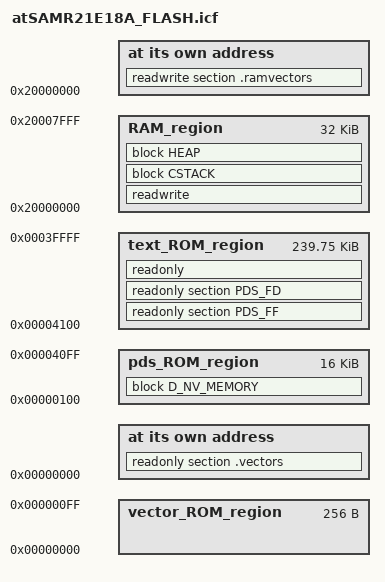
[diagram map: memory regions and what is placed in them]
/**
 * \file
 *
 * \brief Linker script for running in internal FLASH on the SAMR21E18A and SAMR21G18A
 *
 * Copyright (c) 2013 Atmel Corporation. All rights reserved.
 *
 * \asf_license_start
 *
 * \page License
 *
 * Redistribution and use in source and binary forms, with or without
 * modification, are permitted provided that the following conditions are met:
 *
 * 1. Redistributions of source code must retain the above copyright notice,
 *    this list of conditions and the following disclaimer.
 *
 * 2. Redistributions in binary form must reproduce the above copyright notice,
 *    this list of conditions and the following disclaimer in the documentation
 *    and/or other materials provided with the distribution.
 *
 * 3. The name of Atmel may not be used to endorse or promote products derived
 *    from this software without specific prior written permission.
 *
 * 4. This software may only be redistributed and used in connection with an
 *    Atmel microcontroller product.
 *
 * THIS SOFTWARE IS PROVIDED BY ATMEL "AS IS" AND ANY EXPRESS OR IMPLIED
 * WARRANTIES, INCLUDING, BUT NOT LIMITED TO, THE IMPLIED WARRANTIES OF
 * MERCHANTABILITY, FITNESS FOR A PARTICULAR PURPOSE AND NON-INFRINGEMENT ARE
 * EXPRESSLY AND SPECIFICALLY DISCLAIMED. IN NO EVENT SHALL ATMEL BE LIABLE FOR
 * ANY DIRECT, INDIRECT, INCIDENTAL, SPECIAL, EXEMPLARY, OR CONSEQUENTIAL
 * DAMAGES (INCLUDING, BUT NOT LIMITED TO, PROCUREMENT OF SUBSTITUTE GOODS
 * OR SERVICES; LOSS OF USE, DATA, OR PROFITS; OR BUSINESS INTERRUPTION)
 * HOWEVER CAUSED AND ON ANY THEORY OF LIABILITY, WHETHER IN CONTRACT,
 * STRICT LIABILITY, OR TORT (INCLUDING NEGLIGENCE OR OTHERWISE) ARISING IN
 * ANY WAY OUT OF THE USE OF THIS SOFTWARE, EVEN IF ADVISED OF THE
 * POSSIBILITY OF SUCH DAMAGE.
 *
 * \asf_license_stop
 *
 */

/*###ICF### Section handled by ICF editor, don't touch! ****/
/*-Editor annotation file-*/
/* IcfEditorFile="$TOOLKIT_DIR$\config\ide\IcfEditor\a_v1_0.xml" */
/*-Vector table start*/
define symbol __ICFEDIT_vector_start__ = 0x000400000; /*Add for CMSIS*/
/*-Memory Regions-*/
define symbol __ICFEDIT_region_RAM_start__  = 0x20000000;
define symbol __ICFEDIT_region_RAM_end__    = 0x20007FFF;
define symbol __ICFEDIT_region_vector_ROM_start__  = 0x00000000;
define symbol __ICFEDIT_region_vector_ROM_end__    = 0x000000FF;
define symbol __ICFEDIT_region_pds_ROM_start__  = 0x00000100;
define symbol __ICFEDIT_region_pds_ROM_end__    = 0x00040FF;
define symbol __ICFEDIT_region_text_ROM_start__  = 0x004100;
define symbol __ICFEDIT_region_text_ROM_end__    = 0x0003FFFF;

/*-Sizes-*/
define symbol __ICFEDIT_size_cstack__        = 0x800;
define symbol __ICFEDIT_size_heap__          = 0x200;
define symbol D_NV_MEMORY_START = 0x400;
define symbol _D_NV_MEMORY_SIZE = 0x4000;

export symbol __ICFEDIT_vector_start__; /*Add for CMSIS*/
/**** End of ICF editor section. ###ICF###*/

define memory mem with size   = 4G;
define region RAM_region     = mem:[from __ICFEDIT_region_RAM_start__ to __ICFEDIT_region_RAM_end__];
define region vector_ROM_region     = mem:[from __ICFEDIT_region_vector_ROM_start__ to __ICFEDIT_region_vector_ROM_end__];
define region pds_ROM_region        = mem:[from __ICFEDIT_region_pds_ROM_start__ to __ICFEDIT_region_pds_ROM_end__];
define region text_ROM_region       = mem:[from __ICFEDIT_region_text_ROM_start__ to __ICFEDIT_region_text_ROM_end__];

define block CSTACK    with alignment = 8, size = __ICFEDIT_size_cstack__   { };
define block HEAP      with alignment = 8, size = __ICFEDIT_size_heap__     { };
define block D_NV_MEMORY with size = _D_NV_MEMORY_SIZE, alignment = 8 { };

initialize by copy { readwrite };
do not initialize  { section .noinit };

place at address mem:__ICFEDIT_region_vector_ROM_start__ { readonly section .vectors };
place at address mem:__ICFEDIT_region_RAM_start__ { readwrite section .ramvectors };
place in text_ROM_region          { readonly section PDS_FF};    /* PDS files descriptors segment */
place in text_ROM_region          { readonly section PDS_FD};    /* PDS directories descriptors segment */
place in pds_ROM_region           { block D_NV_MEMORY };
place in text_ROM_region          { readonly };
place in RAM_region          { readwrite,,block CSTACK,  block HEAP };
